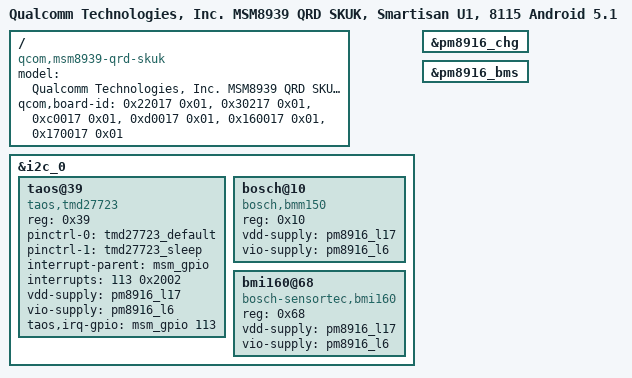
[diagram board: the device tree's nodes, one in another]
/* Copyright (c) 2014, The Linux Foundation. All rights reserved.
 *
 * This program is free software; you can redistribute it and/or modify
 * it under the terms of the GNU General Public License version 2 and
 * only version 2 as published by the Free Software Foundation.
 *
 * This program is distributed in the hope that it will be useful,
 * but WITHOUT ANY WARRANTY; without even the implied warranty of
 * MERCHANTABILITY or FITNESS FOR A PARTICULAR PURPOSE.  See the
 * GNU General Public License for more details.
 */

/dts-v1/;

#define CONFIG_VENDOR_SMARTISAN

#include "msm8939.dtsi"
#include "msm8939-qrd-skuk.dtsi"
#include "u1-msm8939-special-p1.dtsi"

/ {
	model = "Qualcomm Technologies, Inc. MSM8939 QRD SKUK, Smartisan U1, 8115 Android 5.1";
	compatible = "qcom,msm8939-qrd-skuk", "qcom,msm8939-qrd", "qcom,msm8939",
			   "qcom,qrd", "u1-msm8939", "qcom,u1";

	qcom,board-id = <0x22017 0x01>, <0x30217 0x01>, <0xc0017 0x01>, <0xd0017 0x01>, <0x160017 0x01>, <0x170017 0x01>;
};

&i2c_0 { /* BLSP1 QUP2 */
	taos@39 {
		compatible = "taos,tmd27723";
		reg = <0x39>;
		pinctrl-names = "default","sleep";
		pinctrl-0 = <&tmd27723_default>;
		pinctrl-1 = <&tmd27723_sleep>;
		interrupt-parent = <&msm_gpio>;
		interrupts = <113 0x2002>;
		vdd-supply = <&pm8916_l17>;
		vio-supply = <&pm8916_l6>;
		taos,irq-gpio = <&msm_gpio 113 0x2002>;
	};
	bosch@10 {
		compatible = "bosch,bmm150";
		reg = <0x10>;
		vdd-supply = <&pm8916_l17>;
		vio-supply = <&pm8916_l6>;
	};
	bmi160@68 {
		compatible = "bosch-sensortec,bmi160";
		reg = <0x68>;
		vdd-supply = <&pm8916_l17>;
		vio-supply = <&pm8916_l6>;
	};
};

&pm8916_chg {
	status = "ok";
};

&pm8916_bms {
	status = "ok";
};
